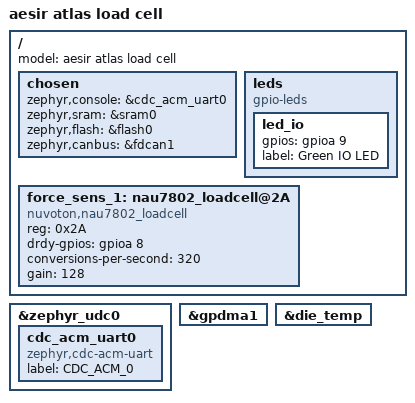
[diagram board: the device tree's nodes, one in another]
/dts-v1/;
#include "atlas-common.dtsi"

/ {
	model = "aesir atlas load cell";

	#address-cells = <1>;
	#size-cells = <1>;

	chosen {
		zephyr,console = &cdc_acm_uart0;
		zephyr,sram = &sram0;
		zephyr,flash = &flash0;
		zephyr,canbus = &fdcan1;
	};

	leds {
        compatible = "gpio-leds";

        led_io: led_io {
            gpios = <&gpioa 9 GPIO_ACTIVE_HIGH>;
            label = "Green IO LED";
        };
    };

	force_sens_1: nau7802_loadcell@2A {
		compatible = "nuvoton,nau7802_loadcell";
		reg = <0x2A>;
		drdy-gpios = <&gpioa 8 GPIO_ACTIVE_HIGH>;
		conversions-per-second = <320>; //SPS
		gain = <128>;
	};
};

&zephyr_udc0 {
	cdc_acm_uart0: cdc_acm_uart0 {
		compatible = "zephyr,cdc-acm-uart";
		label = "CDC_ACM_0";
	};
	status = "okay";
};

&gpdma1 {
	status = "okay";
};

&die_temp {
	status = "okay";
};
